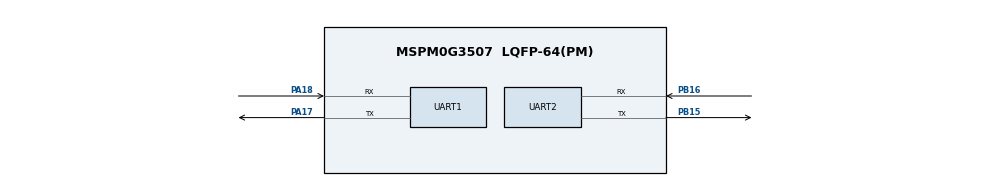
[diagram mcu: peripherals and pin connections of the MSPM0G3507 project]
/**
 * These arguments were used when this file was generated. They will be automatically applied on subsequent loads
 * via the GUI or CLI. Run CLI with '--help' for additional information on how to override these arguments.
 * @cliArgs --device "MSPM0G350X" --part "Default" --package "LQFP-64(PM)" --product "mspm0_sdk@2.04.00.06"
 * @v2CliArgs --device "MSPM0G3507" --package "LQFP-64(PM)" --product "mspm0_sdk@2.04.00.06"
 * @versions {"tool":"1.23.0+4000"}
 */

/**
 * Import the modules used in this configuration.
 */
const ADC12         = scripting.addModule("/ti/driverlib/ADC12", {}, false);
const ADC121        = ADC12.addInstance();
const SYSCTL        = scripting.addModule("/ti/driverlib/SYSCTL");
const TIMER         = scripting.addModule("/ti/driverlib/TIMER", {}, false);
const TIMER1        = TIMER.addInstance();
const UART          = scripting.addModule("/ti/driverlib/UART", {}, false);
const UART1         = UART.addInstance();
const UART2         = UART.addInstance();
const ProjectConfig = scripting.addModule("/ti/project_config/ProjectConfig");

/**
 * Write custom configuration values to the imported modules.
 */
ADC121.$name                             = "ADC12_0";
ADC121.repeatMode                        = true;
ADC121.trigSrc                           = "DL_ADC12_TRIG_SRC_EVENT";
ADC121.adcMem0trig                       = "DL_ADC12_TRIGGER_MODE_TRIGGER_NEXT";
ADC121.powerDownMode                     = "DL_ADC12_POWER_DOWN_MODE_MANUAL";
ADC121.sampleTime0                       = "62.5ns";
ADC121.enabledInterrupts                 = ["DL_ADC12_INTERRUPT_DMA_DONE"];
ADC121.configureDMA                      = true;
ADC121.sampCnt                           = 1;
ADC121.enabledDMATriggers                = ["DL_ADC12_DMA_MEM0_RESULT_LOADED"];
ADC121.subChanID                         = 1;
ADC121.adcMem0chansel                    = "DL_ADC12_INPUT_CHAN_4";
ADC121.DMA_CHANNEL.$name                 = "DMA_CH0";
ADC121.DMA_CHANNEL.addressMode           = "f2b";
ADC121.DMA_CHANNEL.srcLength             = "HALF_WORD";
ADC121.DMA_CHANNEL.dstLength             = "HALF_WORD";
ADC121.DMA_CHANNEL.configureTransferSize = true;
ADC121.DMA_CHANNEL.transferSize          = 1024;
ADC121.peripheral.adcPin4.$assign        = "PB25";
ADC121.adcPin4Config.$name               = "ti_driverlib_gpio_GPIOPinGeneric0";

const Board = scripting.addModule("/ti/driverlib/Board", {}, false);

SYSCTL.forceDefaultClkConfig = true;

TIMER1.$name                       = "TIMER_0";
TIMER1.timerMode                   = "PERIODIC";
TIMER1.timerPeriod                 = "1us";
TIMER1.event1PublisherChannel      = 1;
TIMER1.event1ControllerInterruptEn = ["ZERO_EVENT"];
TIMER1.timerStartTimer             = true;

UART1.$name                            = "UART_1";
UART1.enableFIFO                       = true;
UART1.rxFifoThreshold                  = "DL_UART_RX_FIFO_LEVEL_ONE_ENTRY";
UART1.peripheral.$assign               = "UART1";
UART1.peripheral.rxPin.$assign         = "PA18";
UART1.peripheral.txPin.$assign         = "PA17";
UART1.txPinConfig.direction            = scripting.forceWrite("OUTPUT");
UART1.txPinConfig.hideOutputInversion  = scripting.forceWrite(false);
UART1.txPinConfig.onlyInternalResistor = scripting.forceWrite(false);
UART1.txPinConfig.passedPeripheralType = scripting.forceWrite("Digital");
UART1.txPinConfig.$name                = "ti_driverlib_gpio_GPIOPinGeneric3";
UART1.rxPinConfig.hideOutputInversion  = scripting.forceWrite(false);
UART1.rxPinConfig.onlyInternalResistor = scripting.forceWrite(false);
UART1.rxPinConfig.passedPeripheralType = scripting.forceWrite("Digital");
UART1.rxPinConfig.$name                = "ti_driverlib_gpio_GPIOPinGeneric4";

UART2.$name                            = "UART_2";
UART2.enableFIFO                       = true;
UART2.rxFifoThreshold                  = "DL_UART_RX_FIFO_LEVEL_ONE_ENTRY";
UART2.targetBaudRate                   = 115200;
UART2.peripheral.$assign               = "UART2";
UART2.peripheral.rxPin.$assign         = "PB16";
UART2.peripheral.txPin.$assign         = "PB15";
UART2.txPinConfig.direction            = scripting.forceWrite("OUTPUT");
UART2.txPinConfig.hideOutputInversion  = scripting.forceWrite(false);
UART2.txPinConfig.onlyInternalResistor = scripting.forceWrite(false);
UART2.txPinConfig.passedPeripheralType = scripting.forceWrite("Digital");
UART2.txPinConfig.$name                = "ti_driverlib_gpio_GPIOPinGeneric5";
UART2.rxPinConfig.hideOutputInversion  = scripting.forceWrite(false);
UART2.rxPinConfig.onlyInternalResistor = scripting.forceWrite(false);
UART2.rxPinConfig.passedPeripheralType = scripting.forceWrite("Digital");
UART2.rxPinConfig.$name                = "ti_driverlib_gpio_GPIOPinGeneric6";

ProjectConfig.genLibCMSIS = true;

/**
 * Pinmux solution for unlocked pins/peripherals. This ensures that minor changes to the automatic solver in a future
 * version of the tool will not impact the pinmux you originally saw.  These lines can be completely deleted in order to
 * re-solve from scratch.
 */
ADC121.DMA_CHANNEL.peripheral.$suggestSolution = "DMA_CH0";
ADC121.peripheral.$suggestSolution             = "ADC0";
Board.peripheral.$suggestSolution              = "DEBUGSS";
Board.peripheral.swclkPin.$suggestSolution     = "PA20";
Board.peripheral.swdioPin.$suggestSolution     = "PA19";
SYSCTL.peripheral.$suggestSolution             = "SYSCTL";
TIMER1.peripheral.$suggestSolution             = "TIMA0";
